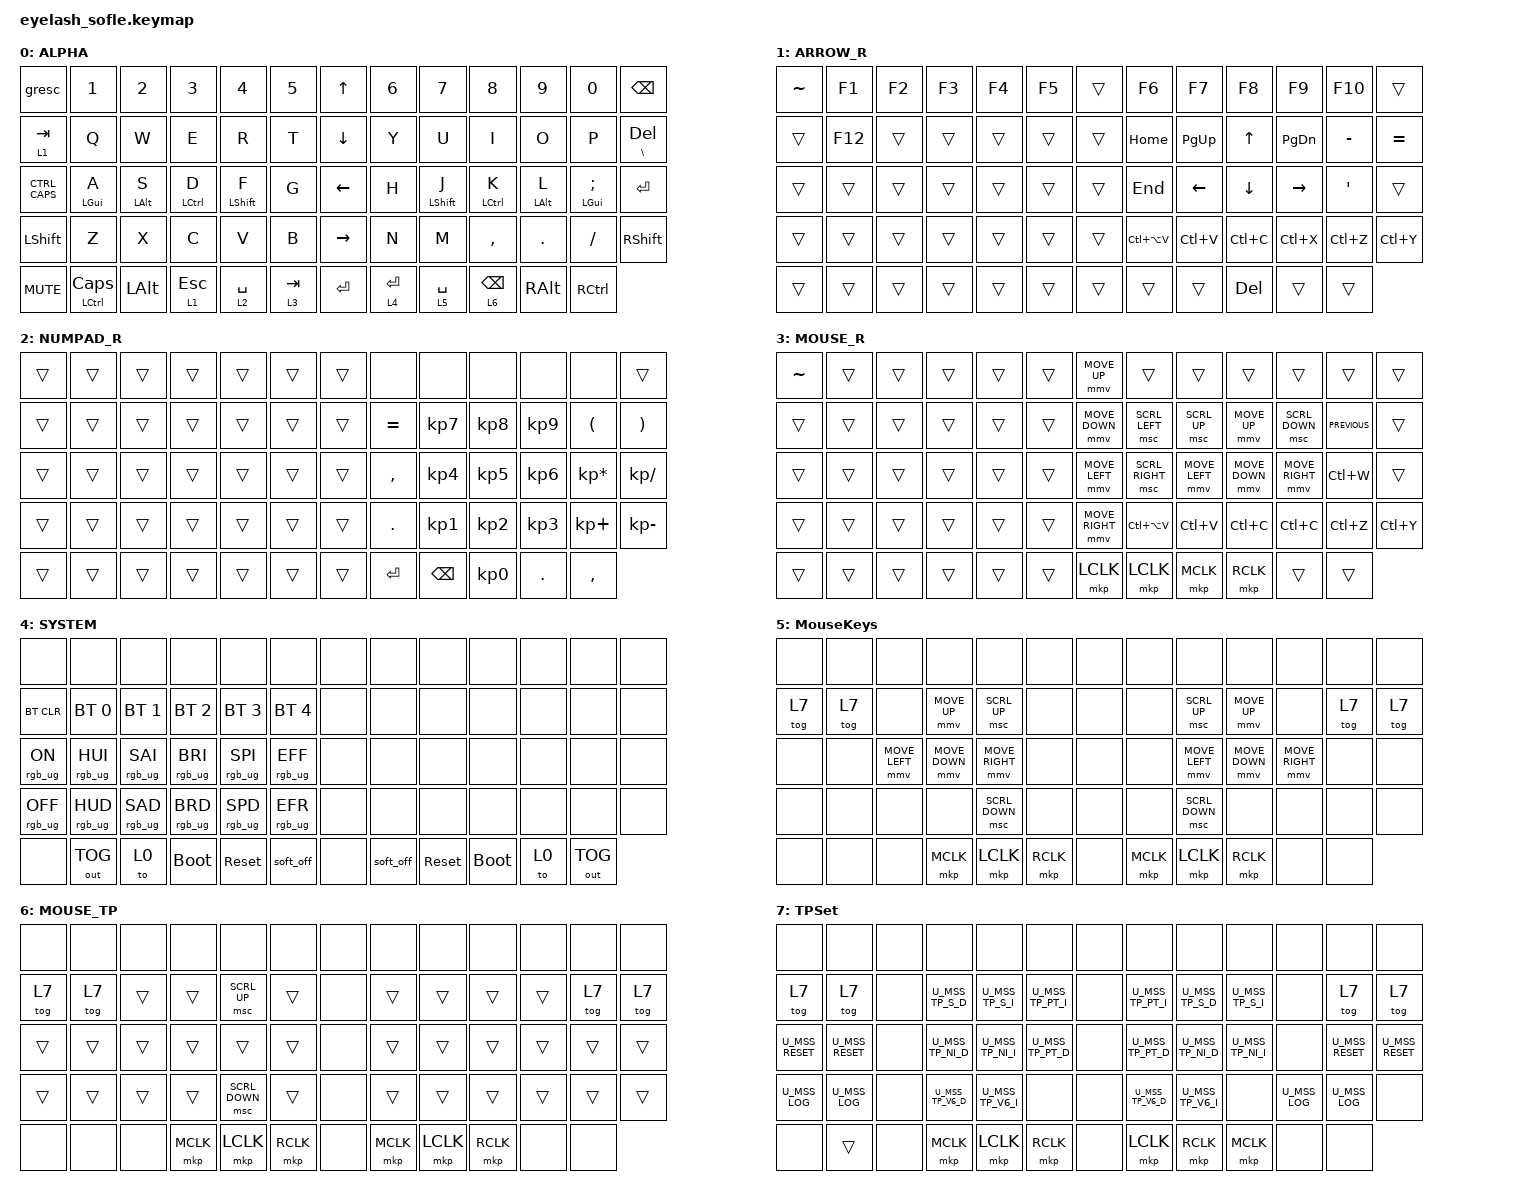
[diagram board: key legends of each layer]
#define ZMK_POINTING_DEFAULT_MOVE_VAL 1200  // 600
#define ZMK_POINTING_DEFAULT_SCRL_VAL 25   // 10

#include <input/processors.dtsi>
#include <zephyr/dt-bindings/input/input-event-codes.h>
#include <behaviors.dtsi>
#include <dt-bindings/zmk/bt.h>
#include <dt-bindings/zmk/keys.h>
#include <dt-bindings/zmk/outputs.h>
#include <dt-bindings/zmk/pointing.h>
#include <dt-bindings/zmk/rgb.h>

#define ALPHA 0
#define ARROW_R 1
#define NUMPAD_R 2
#define MOUSE_R 3
#define SYSTEM 4
#define MouseKeys 5
#define MOUSE_TP 6
#define TPSet 7

// trackpoint setting start

#define HAS_MOUSE_KEYS
#define HAS_MOUSE_TP
// #include "include/mouse_tp.dtsi" // dh
#define MOUSE_PS2_DT_PRESENT

#ifdef HAS_MOUSE_KEYS
  #include <dt-bindings/zmk/mouse.h>
  #include <behaviors/mouse_keys.dtsi>
#endif  // HAS_MOUSE_KEYS

#ifdef HAS_MOUSE_TP
  #include "include/mouse_tp.dtsi"
#endif  // HAS_MOUSE_TP

#ifdef HAS_MOUSE_KEYS
  #define U_THUMB_INNER &mo 5
#else
  #define U_THUMB_INNER &none
#endif  // HAS_MOUSE_KEYS

#ifdef HAS_MOUSE_TP
  #define U_TOG_TP_SET &tog 7
#else
  #define U_TOG_TP_SET &none
#endif  // HAS_MOUSE_TP

// trackpoint setting end

&mmv_input_listener { input-processors = <&zip_xy_scaler 2 1>; };

&msc_input_listener { input-processors = <&zip_scroll_scaler 2 1>; };

&msc {
    acceleration-exponent = <1>;      // 0
    time-to-max-speed-ms = <100>;       // 300
    delay-ms = <0>;                   // 0
};

&mmv {
    time-to-max-speed-ms = <500>;
    acceleration-exponent = <1>;
    trigger-period-ms = <16>;
};

/ {
    scroll_encoder: scroll_encoder {
        compatible = "zmk,behavior-sensor-rotate";
        #sensor-binding-cells = <0>;
        bindings = <&msc SCRL_DOWN>, <&msc SCRL_UP>;

        tap-ms = <100>;
    };

    HOME_ROW: HOME_ROW {
        compatible = "zmk,behavior-hold-tap";
        label = "HOME_ROW";
        bindings = <&kp>, <&kp>;

        #binding-cells = <2>;
        flavor = "tap-preferred";
        tapping-term-ms = <200>;
    };

    CTRL_CAPS: CTRL_CAPS {
        compatible = "zmk,behavior-tap-dance";
        label = "CTRL_CAPS";
        #binding-cells = <0>;
        bindings = <&kp LCTRL>, <&kp CAPSLOCK>;
    };

    behaviors {
    };

    combos {
        compatible = "zmk,combos";

        LSYSL {
            bindings = <&tog 7>;
            key-positions = <57 18>;
        };

        RSYSL {
            bindings = <&tog 7>;
            key-positions = <59 20>;
        };

        HANGUL_1 {
            bindings = <&kp RIGHT_ALT>;
            key-positions = <18 31>;
        };

        HANGUL_2 {
            bindings = <&kp RIGHT_ALT>;
            key-positions = <20 33>;
        };

        HANGUL_3 {
            bindings = <&kp RIGHT_ALT>;
            key-positions = <33 46>;
        };

        HANGUL_4 {
            bindings = <&kp RIGHT_ALT>;
            key-positions = <31 44>;
        };

        BT_SEL_4 {
            bindings = <&bt BT_SEL 4>;
            key-positions = <1 14>;
        };

        BT_SEL_3 {
            bindings = <&bt BT_SEL 3>;
            key-positions = <2 15>;
        };

        BT_SEL_2 {
            bindings = <&bt BT_SEL 2>;
            key-positions = <3 16>;
        };

        BT_SEL_1 {
            bindings = <&bt BT_SEL 1>;
            key-positions = <17 4>;
        };

        BT_SEL_0 {
            bindings = <&bt BT_SEL 0>;
            key-positions = <5 18>;
        };

        COMBO_CUT {
            bindings = <&kp LC(X)>;
            key-positions = <40 41>;
        };

        COMBO_COPY {
            bindings = <&kp LC(C)>;
            key-positions = <41 42>;
        };

        COMBO_PASTE {
            bindings = <&kp LC(V)>;
            key-positions = <42 43>;
        };

        COMBO_PASTESPECIAL {
            bindings = <&kp LA(LC(V))>;
            key-positions = <43 44>;
        };
    };

    keymap {
        compatible = "zmk,keymap";

        ALPHA {
            bindings = <
&gresc      &kp N1                &kp N2                &kp N3             &kp N4                  &kp N5       &kp UP_ARROW     &kp N6       &kp N7                  &kp N8             &kp N9                &kp N0                   &kp BACKSPACE
&lt 1 TAB   &kp Q                 &kp W                 &kp E              &kp R                   &kp T        &kp DOWN_ARROW   &kp Y        &kp U                   &kp I              &kp O                 &kp P                    &mt BACKSLASH DELETE
&CTRL_CAPS  &HOME_ROW LEFT_GUI A  &HOME_ROW LEFT_ALT S  &HOME_ROW LCTRL D  &HOME_ROW LEFT_SHIFT F  &kp G        &kp LEFT_ARROW   &kp H        &HOME_ROW LEFT_SHIFT J  &HOME_ROW LCTRL K  &HOME_ROW LEFT_ALT L  &HOME_ROW LEFT_GUI SEMI  &kp ENTER
&kp LSHFT   &kp Z                 &kp X                 &kp C              &kp V                   &kp B        &kp RIGHT_ARROW  &kp N        &kp M                   &kp COMMA          &kp DOT               &kp FSLH                 &kp RSHIFT
&kp C_MUTE  &mt LCTRL CAPSLOCK    &kp LEFT_ALT          &lt 1 ESCAPE       &lt 2 SPACE             &lt 3 TAB    &kp ENTER        &lt 4 ENTER  &lt 5 SPACE             &lt 6 BACKSPACE    &kp RIGHT_ALT         &kp RCTRL
            >;
            sensor-bindings = <&scroll_encoder>;
            display-name = "ALPHA";
            label = "ALPHA";
        };

        ARROW_R {
            bindings = <
&kp TILDE  &kp F1   &kp F2  &kp F3  &kp F4  &kp F5    &trans  &kp F6         &kp F7       &kp F8      &kp F9         &kp F10         &trans
&trans     &kp F12  &trans  &trans  &trans  &trans    &trans  &kp HOME       &kp PAGE_UP  &kp UP      &kp PAGE_DOWN  &kp MINUS       &kp EQUAL
&trans     &trans   &trans  &trans  &trans  &trans    &trans  &kp END        &kp LEFT     &kp DOWN    &kp RIGHT      &kp APOSTROPHE  &trans
&trans     &trans   &trans  &trans  &trans  &trans    &trans  &kp LC(LA(V))  &kp LC(V)    &kp LC(C)   &kp LC(X)      &kp LC(Z)       &kp LC(Y)
&trans     &trans   &trans  &trans  &trans  &trans    &trans  &trans         &trans       &kp DELETE  &trans         &trans
            >;
            display-name = "ARROW_R";
            sensor-bindings = <&inc_dec_kp C_VOLUME_UP C_VOLUME_DOWN>;
            label = "ARROW_R";
        };

        NUMPAD_R {
            bindings = <
&trans  &trans  &trans  &trans  &trans  &trans    &trans  &none       &none            &none            &none            &none                 &trans
&trans  &trans  &trans  &trans  &trans  &trans    &trans  &kp EQUAL   &kp KP_NUMBER_7  &kp KP_NUMBER_8  &kp KP_NUMBER_9  &kp LEFT_PARENTHESIS  &kp RIGHT_PARENTHESIS
&trans  &trans  &trans  &trans  &trans  &trans    &trans  &kp COMMA   &kp KP_NUMBER_4  &kp KP_NUMBER_5  &kp KP_NUMBER_6  &kp KP_ASTERISK       &kp KP_DIVIDE
&trans  &trans  &trans  &trans  &trans  &trans    &trans  &kp PERIOD  &kp KP_NUMBER_1  &kp KP_NUMBER_2  &kp KP_NUMBER_3  &kp KP_PLUS           &kp KP_MINUS
&trans  &trans  &trans  &trans  &trans  &trans    &trans  &kp ENTER   &kp BACKSPACE    &kp KP_NUMBER_0  &kp PERIOD       &kp COMMA
            >;
            sensor-bindings = <&inc_dec_kp C_VOLUME_UP C_VOLUME_DOWN>;
            label = "NUMPAD_R";
        };

        MOUSE_R {
            label = "MOUSE_R";
            display-name = "MOUSE_R";
            bindings = <
&kp TILDE  &trans  &trans  &trans  &trans  &trans    &mmv MOVE_UP     &trans           &trans          &trans          &trans           &trans          &trans
&trans     &trans  &trans  &trans  &trans  &trans    &mmv MOVE_DOWN   &msc SCRL_LEFT   &msc SCRL_UP    &mmv MOVE_UP    &msc SCRL_DOWN   &kp C_PREVIOUS  &trans
&trans     &trans  &trans  &trans  &trans  &trans    &mmv MOVE_LEFT   &msc SCRL_RIGHT  &mmv MOVE_LEFT  &mmv MOVE_DOWN  &mmv MOVE_RIGHT  &kp LC(W)       &trans
&trans     &trans  &trans  &trans  &trans  &trans    &mmv MOVE_RIGHT  &kp LC(LA(V))    &kp LC(V)       &kp LC(C)       &kp LC(C)        &kp LC(Z)       &kp LC(Y)
&trans     &trans  &trans  &trans  &trans  &trans    &mkp LCLK        &mkp LCLK        &mkp MCLK       &mkp RCLK       &trans           &trans
            >;
            sensor-bindings = <&scroll_encoder>;
        };


        SYSTEM {
            bindings = <
&none            &none            &none            &none            &none            &none              &none  &none      &none       &none        &none  &none         &none
&bt BT_CLR       &bt BT_SEL 0     &bt BT_SEL 1     &bt BT_SEL 2     &bt BT_SEL 3     &bt BT_SEL 4       &none  &none      &none       &none        &none  &none         &none
&rgb_ug RGB_ON   &rgb_ug RGB_HUI  &rgb_ug RGB_SAI  &rgb_ug RGB_BRI  &rgb_ug RGB_SPI  &rgb_ug RGB_EFF    &none  &none      &none       &none        &none  &none         &none
&rgb_ug RGB_OFF  &rgb_ug RGB_HUD  &rgb_ug RGB_SAD  &rgb_ug RGB_BRD  &rgb_ug RGB_SPD  &rgb_ug RGB_EFR    &none  &none      &none       &none        &none  &none         &none
&none            &out OUT_TOG     &to 0            &bootloader      &sys_reset       &soft_off          &none  &soft_off  &sys_reset  &bootloader  &to 0  &out OUT_TOG
            >;
            label = "SYSTEM";
        };

// trackpoint setting start

#ifdef HAS_MOUSE_KEYS

		MouseKeys {
			label = "MouseKeys";
			display-name = "MouseKeys";
			bindings = <
&none                    &none                    &none                    &none                    &none                    &none                    &none                    &none                    &none                    &none                    &none                    &none                     &none
U_TOG_TP_SET             U_TOG_TP_SET             &none                    &mmv MOVE_UP             &msc SCRL_UP             &none                    &none                    &none                    &msc SCRL_UP             &mmv MOVE_UP             &none                    U_TOG_TP_SET              U_TOG_TP_SET
&none                    &none                    &mmv MOVE_LEFT           &mmv MOVE_DOWN           &mmv MOVE_RIGHT          &none                    &none                    &none                    &mmv MOVE_LEFT           &mmv MOVE_DOWN           &mmv MOVE_RIGHT          &none                     &none
&none                    &none                    &none                    &none                    &msc SCRL_DOWN           &none                    &none                    &none                    &msc SCRL_DOWN           &none                    &none                    &none                     &none
&none                    &none                    &none                    &mkp MCLK                &mkp LCLK                &mkp RCLK                &none                    &mkp MCLK                &mkp LCLK                &mkp RCLK                &none                    &none
			>;
		};

#endif

#ifdef HAS_MOUSE_TP
		MOUSE_TP {
			label = "MOUSE_TP";
			display-name = "MOUSE_TP";
			bindings = <
&none                    &none                    &none                    &none                    &none                    &none                    &none                    &none                    &none                    &none                    &none                    &none                    &none
U_TOG_TP_SET             U_TOG_TP_SET             &trans                   &trans                   &msc SCRL_UP             &trans                   &none                    &trans                   &trans                   &trans                   &trans                   U_TOG_TP_SET             U_TOG_TP_SET
&trans                   &trans                   &trans                   &trans                   &trans                   &trans                   &none                    &trans                   &trans                   &trans                   &trans                   &trans                   &trans
&trans                   &trans                   &trans                   &trans                   &msc SCRL_DOWN           &trans                   &none                    &trans                   &trans                   &trans                   &trans                   &trans                   &trans
&none                    &none                    &none                    &mkp MCLK                &mkp LCLK                &mkp RCLK                &none                    &mkp MCLK                &mkp LCLK                &mkp RCLK                &none                    &none
			>;
		};

		TPSet {
			label = "TP_Set";
			display-name = "TPSet";
			bindings = <
&none                    &none                    &none                    &none                    &none                    &none                    &none                    &none                    &none                    &none                    &none                    &none                    &none
U_TOG_TP_SET             U_TOG_TP_SET             &none                    U_MSS_TP_S_D             U_MSS_TP_S_I             U_MSS_TP_PT_I            &none                    U_MSS_TP_PT_I            U_MSS_TP_S_D             U_MSS_TP_S_I             &none                    U_TOG_TP_SET             U_TOG_TP_SET
U_MSS_RESET              U_MSS_RESET              &none                    U_MSS_TP_NI_D            U_MSS_TP_NI_I            U_MSS_TP_PT_D            &none                    U_MSS_TP_PT_D            U_MSS_TP_NI_D            U_MSS_TP_NI_I            &none                    U_MSS_RESET              U_MSS_RESET
U_MSS_LOG                U_MSS_LOG                &none                    U_MSS_TP_V6_D            U_MSS_TP_V6_I            &none                    &none                    U_MSS_TP_V6_D            U_MSS_TP_V6_I            &none                    U_MSS_LOG                U_MSS_LOG                &none
&none                    &trans                   &none                    &mkp MCLK                &mkp LCLK                &mkp RCLK                &none                    &mkp LCLK                &mkp RCLK                &mkp MCLK                &none                    &none
			>;
		};

#endif

// trackpoint setting end

	};
};
